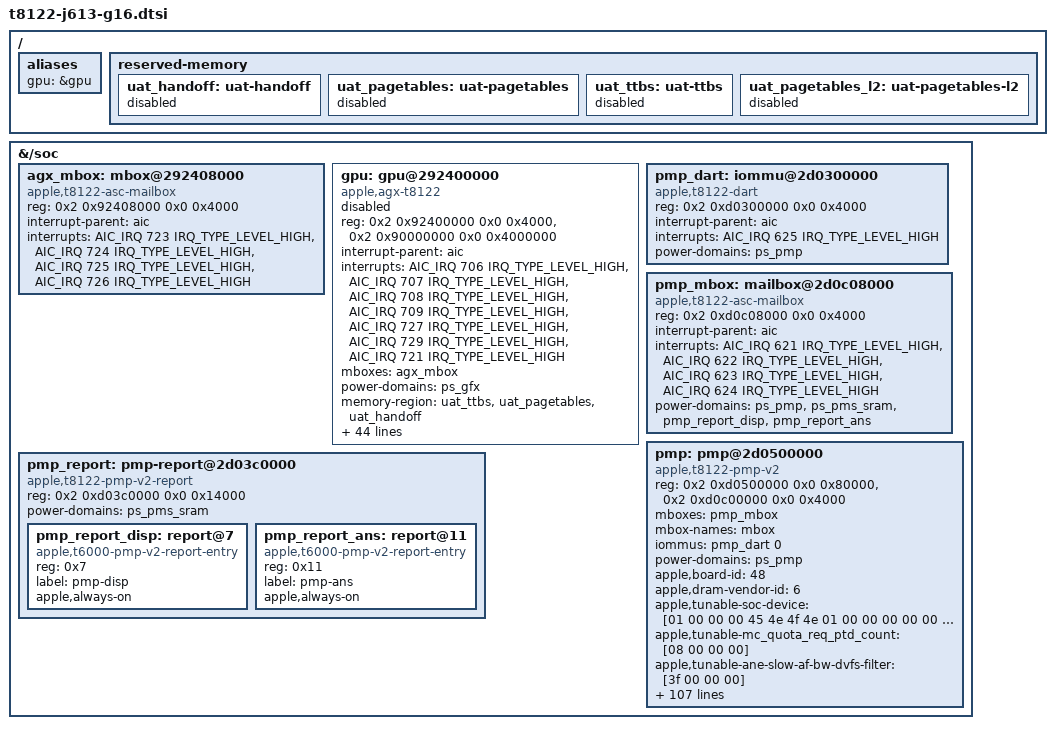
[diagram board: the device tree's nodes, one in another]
// SPDX-License-Identifier: GPL-2.0+ OR MIT
/*
 * J613 GPU on the 25G83 (RTKit-3255.160.4) firmware path, and its PMP.
 * Generated by make-j613-g16-dtsi.py from the J613 ADT iBoot 25G83 passes to macOS
 * (/arm-io/sgx, pmp, iop-pmp-nub, dart-pmp, /chosen). See the script for the contract.
 */

/ {
	aliases {
		gpu = &gpu;	/* m1n1 dt_set_gpu() finds the node through this alias */
	};

	reserved-memory {
		/* Filled, linked and enabled by the bootloader; no placeholder reg. */
		uat_handoff: uat-handoff { status = "disabled"; };
		uat_pagetables: uat-pagetables { status = "disabled"; };
		uat_ttbs: uat-ttbs { status = "disabled"; };
		uat_pagetables_l2: uat-pagetables-l2 { status = "disabled"; };
	};
};

&{/soc} {
	agx_mbox: mbox@292408000 {
		compatible = "apple,t8122-asc-mailbox", "apple,asc-mailbox-v4";
		reg = <0x2 0x92408000 0x0 0x4000>;
		interrupt-parent = <&aic>;
		interrupts = <AIC_IRQ 723 IRQ_TYPE_LEVEL_HIGH>,
			<AIC_IRQ 724 IRQ_TYPE_LEVEL_HIGH>,
			<AIC_IRQ 725 IRQ_TYPE_LEVEL_HIGH>,
			<AIC_IRQ 726 IRQ_TYPE_LEVEL_HIGH>;
		interrupt-names = "send-empty", "send-not-empty",
			"recv-empty", "recv-not-empty";
		#mbox-cells = <0>;
	};

	gpu: gpu@292400000 {
		compatible = "apple,agx-t8122";
		reg = <0x2 0x92400000 0x0 0x4000>,
			<0x2 0x90000000 0x0 0x4000000>;
		reg-names = "asc", "sgx";
		interrupt-parent = <&aic>;
		interrupts = <AIC_IRQ 706 IRQ_TYPE_LEVEL_HIGH>,
			<AIC_IRQ 707 IRQ_TYPE_LEVEL_HIGH>,
			<AIC_IRQ 708 IRQ_TYPE_LEVEL_HIGH>,
			<AIC_IRQ 709 IRQ_TYPE_LEVEL_HIGH>,
			<AIC_IRQ 727 IRQ_TYPE_LEVEL_HIGH>,
			<AIC_IRQ 729 IRQ_TYPE_LEVEL_HIGH>,
			<AIC_IRQ 721 IRQ_TYPE_LEVEL_HIGH>;
		mboxes = <&agx_mbox>;
		power-domains = <&ps_gfx>;
		/* The bootloader replaces these with all six regions, in g16 order. */
		memory-region = <&uat_ttbs>, <&uat_pagetables>, <&uat_handoff>;
		memory-region-names = "ttbs", "pagetables", "handoff";
		apple,pmp = <&pmp>;
		apple,j613-native-gpu;

		/* Controller gains copied from the J613 ADT sgx gpu-* values. */
		apple,min-sram-microvolt = <790000>;
		/* ADT gpu-perf-base-pstate */
		apple,perf-base-pstate = <1>;

		/* ADT /arm-io/sgx gpu-* tunables, ADT name minus the "gpu-" prefix */
		apple,avg-power-filter-tc-ms = <40>;
		apple,avg-power-ki-only = <70.0>;
		apple,avg-power-kp = <1.95>;
		apple,avg-power-min-duty-cycle = <30>;
		apple,avg-power-target-filter-tc = <1>;
		apple,fast-die0-integral-gain = <450.0>;
		apple,fast-die0-proportional-gain = <34.0>;
		apple,perf-boost-ce-step = <50>;
		apple,perf-boost-min-util = <90>;
		apple,perf-filter-drop-threshold = <0>;
		apple,perf-filter-time-constant = <5>;
		apple,perf-filter-time-constant2 = <200>;
		apple,perf-integral-gain = <0.7975>;
		apple,perf-integral-gain2 = <0.7975>;
		apple,perf-integral-min-clamp = <0>;
		apple,perf-proportional-gain = <5.4>;
		apple,perf-proportional-gain2 = <5.4>;
		apple,perf-tgt-utilization = <85>;
		apple,power-sample-period = <8>;
		apple,ppm-filter-time-constant-ms = <100>;
		apple,ppm-ki = <97.1>;
		apple,ppm-kp = <2.9>;
		apple,pwr-filter-time-constant = <313>;
		apple,pwr-integral-gain = <0.0202129>;
		apple,pwr-integral-min-clamp = <0>;
		apple,pwr-min-duty-cycle = <30>;
		apple,pwr-proportional-gain = <5.2831855>;
		apple,pwr-sample-period-aic-clks = <200000>;
		apple,se-engagement-criteria = <600>;
		apple,se-filter-time-constant = <9>;
		apple,se-filter-time-constant-1 = <3>;
		apple,se-inactive-threshold = <2500>;
		apple,se-ki = <-50.0>;
		apple,se-ki-1 = <-100.0>;
		apple,se-kp = <-5.0>;
		apple,se-kp-1 = <-10.0>;
		apple,se-reset-criteria = <50>;
		apple,se-target = <1400>;

		apple,fast-die0-release-temp = <80>;
		status = "disabled";
	};

	pmp_report: pmp-report@2d03c0000 {
		compatible = "apple,t8122-pmp-v2-report";
		reg = <0x2 0xd03c0000 0x0 0x14000>;
		power-domains = <&ps_pms_sram>;
		#address-cells = <1>;
		#size-cells = <0>;

		pmp_report_disp: report@7 {
			compatible = "apple,t6000-pmp-v2-report-entry";
			reg = <0x7>;
			label = "pmp-disp";
			#power-domain-cells = <0>;
			apple,always-on;
		};

		pmp_report_ans: report@11 {
			compatible = "apple,t6000-pmp-v2-report-entry";
			reg = <0x11>;
			label = "pmp-ans";
			#power-domain-cells = <0>;
			apple,always-on;
		};
	};

	pmp_dart: iommu@2d0300000 {
		compatible = "apple,t8122-dart", "apple,t8110-dart";
		reg = <0x2 0xd0300000 0x0 0x4000>;
		#iommu-cells = <1>;
		interrupt-parent = <&aic>;
		interrupts = <AIC_IRQ 625 IRQ_TYPE_LEVEL_HIGH>;
		power-domains = <&ps_pmp>;
	};

	pmp_mbox: mailbox@2d0c08000 {
		compatible = "apple,t8122-asc-mailbox", "apple,asc-mailbox-v4";
		reg = <0x2 0xd0c08000 0x0 0x4000>;
		interrupt-parent = <&aic>;
		interrupts = <AIC_IRQ 621 IRQ_TYPE_LEVEL_HIGH>,
			<AIC_IRQ 622 IRQ_TYPE_LEVEL_HIGH>,
			<AIC_IRQ 623 IRQ_TYPE_LEVEL_HIGH>,
			<AIC_IRQ 624 IRQ_TYPE_LEVEL_HIGH>;
		interrupt-names = "send-empty", "send-not-empty",
			"recv-empty", "recv-not-empty";
		#mbox-cells = <0>;
		/* The report entries are listed so fw_devlink seeds DISP/ANS before the PMP starts. */
		power-domains = <&ps_pmp>, <&ps_pms_sram>, <&pmp_report_disp>, <&pmp_report_ans>;
	};

	pmp: pmp@2d0500000 {
		compatible = "apple,t8122-pmp-v2", "apple,t6000-pmp-v2";
		reg = <0x2 0xd0500000 0x0 0x80000>,
		      <0x2 0xd0c00000 0x0 0x4000>;
		reg-names = "pmp", "asc";
		mboxes = <&pmp_mbox>;
		mbox-names = "mbox";
		iommus = <&pmp_dart 0>;
		power-domains = <&ps_pmp>;
		apple,board-id = <48>;
		apple,dram-vendor-id = <6>;
		apple,tunable-soc-device = [01 00 00 00 45 4e 4f 4e 01 00 00 00 00 00 00 00 00 00 00 00 00 00 00 00 01 00 00 00 00 00 00 00 00 00 00 00 00 00 00 00 00 00 00 00 00 00 00 00 00 00 00 00 00 00 00 00 00 00 00 00 00 00 00 00 00 00 00 00 00 00 00 00 00 00 00 00 00 00 00 00 00 00 00 00 00 00 00 00 00 00 00 00 00 00 00 00 00 00 00 00 00 00 00 00 00 00 00 00 00 00 00 00 00 00 00 00 44 43 53 00 00 00 00 00 02 00 00 00 45 4e 4f 4e 01 00 00 00 10 00 00 00 00 00 00 00 00 00 00 00 02 00 00 00 00 00 00 00 00 00 00 00 00 00 00 00 00 00 00 00 00 00 00 00 00 00 00 00 00 00 00 00 00 00 00 00 00 00 00 00 00 00 00 00 00 00 00 00 00 00 00 00 00 00 00 00 00 00 00 00 00 00 00 00 00 00 00 00 00 00 00 00 00 00 00 00 00 00 00 00 00 00 00 00 00 00 00 00 00 00 00 00 41 4d 43 43 00 00 00 00 13 00 00 00 45 4e 4f 4e 01 00 00 00 01 00 00 00 00 00 00 00 00 00 00 00 02 00 00 00 00 00 00 00 00 00 00 00 00 00 00 00 00 00 00 00 00 00 00 00 00 00 00 00 00 00 00 00 00 00 00 00 00 00 00 00 00 00 00 00 00 00 00 00 00 00 00 00 00 00 00 00 00 00 00 00 00 00 00 00 00 00 00 00 00 00 00 00 00 00 00 00 00 00 00 00 00 00 00 00 00 00 00 00 00 00 00 00 49 4f 41 30 00 00 00 00 14 00 00 00 45 4e 4f 4e 01 00 00 00 01 00 00 00 00 00 00 00 00 00 00 00 02 00 00 00 00 00 00 00 00 00 00 00 00 00 00 00 00 00 00 00 00 00 00 00 00 00 00 00 00 00 00 00 00 00 00 00 00 00 00 00 00 00 00 00 00 00 00 00 00 00 00 00 00 00 00 00 00 00 00 00 00 00 00 00 00 00 00 00 00 00 00 00 00 00 00 00 00 00 00 00 00 00 00 00 00 00 00 00 00 00 00 00 49 4f 41 31 00 00 00 00 10 00 00 00 45 4e 4f 4e 01 00 00 00 00 00 00 00 15 00 00 00 00 00 00 00 02 00 00 00 00 00 00 00 00 00 00 00 00 00 00 00 00 00 00 00 00 00 00 00 00 00 00 00 00 00 00 00 00 00 00 00 00 00 00 00 00 00 00 00 00 00 00 00 00 00 00 00 00 00 00 00 00 00 00 00 00 00 00 00 00 00 00 00 00 00 00 00 00 00 00 00 00 00 00 00 00 00 00 00 00 00 00 00 00 00 00 00 53 4f 43 2d 41 4f 4e 00 11 00 00 00 45 4e 4f 4e 01 00 00 00 00 00 00 00 16 00 00 00 00 00 00 00 02 00 00 00 00 00 00 00 00 00 00 00 00 00 00 00 00 00 00 00 00 00 00 00 00 00 00 00 00 00 00 00 00 00 00 00 00 00 00 00 00 00 00 00 00 00 00 00 00 00 00 00 00 00 00 00 00 00 00 00 00 00 00 00 00 00 00 00 00 00 00 00 00 00 00 00 00 00 00 00 00 00 00 00 00 00 00 00 00 00 00 00 53 4f 43 2d 52 45 53 54 03 00 00 00 45 4e 4f 4e 03 00 00 00 01 00 00 00 00 00 00 00 00 00 00 00 00 00 00 00 02 00 00 00 00 00 00 00 00 00 00 00 00 00 00 00 02 00 00 00 00 00 00 00 00 00 00 00 00 00 00 00 00 00 00 00 00 00 00 00 00 00 00 00 00 00 00 00 00 00 00 00 00 00 00 00 00 00 00 00 00 00 00 00 00 00 00 00 00 00 00 00 00 00 00 00 00 00 00 00 00 00 00 00 00 00 00 00 45 41 43 43 30 00 00 00 04 00 00 00 45 4e 4f 4e 03 00 00 00 02 00 00 00 00 00 00 00 00 00 00 00 00 00 00 00 02 00 00 00 00 00 00 00 00 00 00 00 00 00 00 00 02 00 00 00 00 00 00 00 00 00 00 00 00 00 00 00 00 00 00 00 00 00 00 00 00 00 00 00 00 00 00 00 00 00 00 00 00 00 00 00 00 00 00 00 00 00 00 00 00 00 00 00 00 00 00 00 00 00 00 00 00 00 00 00 00 00 00 00 00 00 00 00 50 41 43 43 30 00 00 00 05 00 00 00 5f 58 46 47 03 00 00 00 01 00 00 00 00 00 00 00 00 00 00 00 00 00 00 00 02 00 00 00 00 00 00 00 00 00 00 00 00 00 00 00 02 00 00 00 00 00 00 00 00 00 00 00 00 00 00 00 00 00 00 00 00 00 00 00 00 00 00 00 00 00 00 00 00 00 00 00 00 00 00 00 00 00 00 00 00 00 00 00 00 00 00 00 00 00 00 00 00 00 00 00 00 00 00 00 00 00 00 00 00 00 00 00 41 47 58 00 00 00 00 00 06 00 00 00 45 4e 4f 4e 03 00 00 00 01 00 00 00 00 00 00 00 00 00 00 00 00 00 00 00 02 00 00 00 00 00 00 00 00 00 00 00 00 00 00 00 02 00 00 00 00 00 00 00 00 00 00 00 00 00 00 00 00 00 00 00 00 00 00 00 00 00 00 00 00 00 00 00 00 00 00 00 00 00 00 00 00 00 00 00 00 00 00 00 00 00 00 00 00 00 00 00 00 00 00 00 00 00 00 00 00 00 00 00 00 00 00 00 41 4e 45 30 00 00 00 00 07 00 00 00 45 4e 4f 4e 01 00 00 00 00 00 00 00 00 00 00 00 00 00 00 00 02 00 00 00 00 00 00 00 00 00 00 00 00 00 00 00 00 00 00 00 01 00 00 00 03 00 00 00 00 00 00 00 00 00 00 00 00 00 00 00 00 00 00 00 00 00 00 00 00 00 00 00 00 00 00 00 00 00 00 00 00 00 00 00 00 00 00 00 00 00 00 00 00 00 00 00 00 00 00 00 00 00 00 00 00 00 00 00 00 00 00 00 49 53 50 00 00 00 00 00 08 00 00 00 45 4e 4f 4e 0a 00 00 00 00 00 00 00 00 00 00 00 00 00 00 00 03 00 00 00 02 00 00 00 00 00 00 00 00 00 00 00 00 00 00 00 02 00 00 00 03 00 00 00 00 00 00 00 00 00 00 00 00 00 00 00 00 00 00 00 00 00 00 00 00 00 00 00 00 00 00 00 00 00 00 00 00 00 00 00 00 00 00 00 00 00 00 00 00 00 00 00 00 00 00 00 00 00 00 00 00 00 00 00 00 00 00 00 44 49 53 50 00 00 00 00 09 00 00 00 45 4e 4f 4e 0a 00 00 00 00 00 00 00 00 00 00 00 00 00 00 00 04 00 00 00 02 00 00 00 00 00 00 00 00 00 00 00 00 00 00 00 02 00 00 00 03 00 00 00 00 00 00 00 00 00 00 00 00 00 00 00 00 00 00 00 00 00 00 00 00 00 00 00 00 00 00 00 00 00 00 00 00 00 00 00 00 00 00 00 00 00 00 00 00 00 00 00 00 00 00 00 00 00 00 00 00 00 00 00 00 00 00 00 44 49 53 50 45 58 54 00 0a 00 00 00 45 4e 4f 4e 01 00 00 00 00 00 00 00 00 00 00 00 00 00 00 00 02 00 00 00 00 00 00 00 00 00 00 00 00 00 00 00 00 00 00 00 02 00 00 00 00 00 00 00 00 00 00 00 00 00 00 00 00 00 00 00 00 00 00 00 00 00 00 00 00 00 00 00 00 00 00 00 00 00 00 00 00 00 00 00 00 00 00 00 00 00 00 00 00 00 00 00 00 00 00 00 00 00 00 00 00 00 00 00 00 00 00 00 41 56 45 00 00 00 00 00 0b 00 00 00 45 4e 4f 4e 01 00 00 00 00 00 00 00 14 00 00 00 00 00 00 00 02 00 00 00 00 00 00 00 00 00 00 00 00 00 00 00 00 00 00 00 02 00 00 00 00 00 00 00 00 00 00 00 00 00 00 00 00 00 00 00 00 00 00 00 00 00 00 00 00 00 00 00 00 00 00 00 00 00 00 00 00 00 00 00 00 00 00 00 00 00 00 00 00 00 00 00 00 00 00 00 00 00 00 00 00 00 00 00 00 00 00 00 41 56 44 00 00 00 00 00 0c 00 00 00 45 4e 4f 4e 01 00 00 00 00 00 00 00 00 00 00 00 00 00 00 00 02 00 00 00 00 00 00 00 00 00 00 00 00 00 00 00 00 00 00 00 02 00 00 00 00 00 00 00 00 00 00 00 00 00 00 00 00 00 00 00 00 00 00 00 00 00 00 00 00 00 00 00 00 00 00 00 00 00 00 00 00 00 00 00 00 00 00 00 00 00 00 00 00 00 00 00 00 00 00 00 00 00 00 00 00 00 00 00 00 00 00 00 4d 53 52 00 00 00 00 00 0d 00 00 00 45 4e 4f 4e 01 00 00 00 00 00 00 00 00 00 00 00 00 00 00 00 02 00 00 00 00 00 00 00 00 00 00 00 00 00 00 00 00 00 00 00 02 00 00 00 00 00 00 00 00 00 00 00 00 00 00 00 00 00 00 00 00 00 00 00 00 00 00 00 00 00 00 00 00 00 00 00 00 00 00 00 00 00 00 00 00 00 00 00 00 00 00 00 00 00 00 00 00 00 00 00 00 00 00 00 00 00 00 00 00 00 00 00 4a 50 45 47 00 00 00 00 0e 00 00 00 45 4e 4f 4e 01 00 00 00 00 00 00 00 00 00 00 00 00 00 00 00 02 00 00 00 00 00 00 00 00 00 00 00 00 00 00 00 00 00 00 00 02 00 00 00 03 00 00 00 00 00 00 00 00 00 00 00 00 00 00 00 00 00 00 00 00 00 00 00 00 00 00 00 00 00 00 00 00 00 00 00 00 00 00 00 00 00 00 00 00 00 00 00 00 00 00 00 00 00 00 00 00 00 00 00 00 00 00 00 00 00 00 00 53 43 4f 44 45 43 00 00 0f 00 00 00 5f 52 54 4c 00 00 00 00 00 00 00 00 00 00 00 00 00 00 00 00 00 00 00 00 00 00 00 00 00 00 00 00 00 00 00 00 00 00 00 00 02 00 00 00 00 00 00 00 00 00 00 00 00 00 00 00 00 00 00 00 00 00 00 00 00 00 00 00 00 00 00 00 00 00 00 00 00 00 00 00 00 00 00 00 00 00 00 00 00 00 00 00 00 00 00 00 00 00 00 00 00 00 00 00 00 00 00 00 00 00 00 00 4c 54 52 00 00 00 00 00 12 00 00 00 45 4e 4f 4e 00 00 00 00 00 00 00 00 00 00 00 00 00 00 00 00 02 00 00 00 00 00 00 00 00 00 00 00 00 00 00 00 00 00 00 00 02 00 00 00 00 00 00 00 00 00 00 00 00 00 00 00 00 00 00 00 00 00 00 00 00 00 00 00 00 00 00 00 00 00 00 00 00 00 00 00 00 00 00 00 00 00 00 00 00 00 00 00 00 00 00 00 00 00 00 00 00 00 00 00 00 00 00 00 00 00 00 00 41 4e 53 00 00 00 00 00];
		apple,tunable-mc_quota_req_ptd_count = [08 00 00 00];
		apple,tunable-ane-slow-af-bw-dvfs-filter = [3f 00 00 00];
		apple,tunable-mc_cmd_ptd_count = [02 00 00 00];
		apple,tunable-sochot-sensors = [01 00 00 00 02 00 00 00 03 00 00 00 04 00 00 00 05 00 00 00 06 00 00 00 09 00 00 00 0a 00 00 00 0b 00 00 00];
		apple,tunable-ptd-range = [01 00 00 00 00 00 00 00 01 00 00 00 00 00 00 00 4e 55 4c 4c 00 00 00 00 00 00 00 00 00 00 00 00 02 00 00 00 01 00 00 00 01 00 00 00 00 00 00 00 50 4d 50 2d 53 54 41 54 55 53 00 00 00 00 00 00 03 00 00 00 08 00 00 00 04 00 00 00 00 00 00 00 44 56 46 53 2d 53 54 41 54 45 00 00 00 00 00 00 04 00 00 00 0c 00 00 00 04 00 00 00 00 00 00 00 50 4d 50 54 4f 4f 4c 00 00 00 00 00 00 00 00 00 05 00 00 00 10 00 00 00 10 00 00 00 00 00 00 00 50 4d 53 2d 50 4d 47 52 2d 50 4b 54 00 00 00 00 06 00 00 00 20 00 00 00 10 00 00 00 00 00 00 00 50 4d 53 2d 44 50 45 2d 50 4b 54 00 00 00 00 00 07 00 00 00 30 00 00 00 10 00 00 00 00 00 00 00 50 4d 53 2d 44 45 56 43 2d 50 4b 54 00 00 00 00 09 00 00 00 40 00 00 00 c0 00 00 00 00 00 00 00 53 4f 43 2d 44 45 56 2d 50 4b 54 00 00 00 00 00 0a 00 00 00 00 01 00 00 08 00 00 00 00 00 00 00 53 4f 43 2d 44 45 56 2d 50 53 2d 52 45 51 00 00 0b 00 00 00 08 01 00 00 08 00 00 00 00 00 00 00 53 4f 43 2d 44 45 56 2d 50 53 2d 41 43 4b 00 00 0c 00 00 00 10 01 00 00 10 00 00 00 00 00 00 00 53 4f 43 2d 44 45 56 2d 44 56 46 53 00 00 00 00 0d 00 00 00 20 01 00 00 08 00 00 00 00 00 00 00 53 4f 43 2d 44 45 56 2d 42 57 52 00 00 00 00 00 0e 00 00 00 28 01 00 00 0a 00 00 00 00 00 00 00 4d 43 2d 44 52 56 2d 54 4f 2d 43 54 52 4c 00 00 14 00 00 00 39 01 00 00 01 00 00 00 00 00 00 00 41 56 44 2d 4e 52 47 00 00 00 00 00 00 00 00 00 15 00 00 00 3a 01 00 00 01 00 00 00 00 00 00 00 53 4f 43 2d 41 4f 4e 2d 4e 52 47 00 00 00 00 00 16 00 00 00 3b 01 00 00 01 00 00 00 00 00 00 00 53 4f 43 2d 52 45 53 54 2d 4e 52 47 00 00 00 00 1e 00 00 00 40 01 00 00 09 00 00 00 00 00 00 00 4d 43 2d 43 54 52 4c 2d 54 4f 2d 44 52 56 00 00 1f 00 00 00 49 01 00 00 02 00 00 00 0c 00 00 00 46 41 53 54 2d 44 49 45 2d 43 45 00 00 00 00 00 20 00 00 00 4b 01 00 00 07 00 00 00 0d 00 00 00 53 4d 43 2d 54 4f 2d 50 50 4d 00 00 00 00 00 00 21 00 00 00 52 01 00 00 01 00 00 00 00 00 00 00 50 4d 55 2d 54 4f 2d 43 4c 50 43 00 00 00 00 00 22 00 00 00 53 01 00 00 01 00 00 00 0b 00 00 00 4c 54 53 2d 56 4f 4c 54 2d 43 41 50 00 00 00 00 40 00 00 00 68 01 00 00 05 00 00 00 0e 00 00 00 50 50 4d 2d 54 4f 2d 53 4d 43 00 00 00 00 00 00 41 00 00 00 6d 01 00 00 05 00 00 00 0f 00 00 00 43 4c 50 43 2d 54 4f 2d 53 4d 43 00 00 00 00 00 42 00 00 00 72 01 00 00 08 00 00 00 00 00 00 00 47 46 58 2d 54 4f 2d 53 4d 43 00 00 00 00 00 00 43 00 00 00 7a 01 00 00 02 00 00 00 00 00 00 00 46 41 53 54 2d 44 49 45 2d 54 4f 2d 53 4d 43 00 44 00 00 00 7c 01 00 00 01 00 00 00 00 00 00 00 4d 43 2d 43 54 52 4c 2d 54 4f 2d 53 4d 43 00 00 52 00 00 00 b8 01 00 00 01 00 00 00 00 00 00 00 4c 54 53 2d 54 4f 2d 47 46 58 00 00 00 00 00 00 53 00 00 00 b9 01 00 00 01 00 00 00 00 00 00 00 50 4d 55 2d 54 4f 2d 47 46 58 00 00 00 00 00 00];
		apple,tunable-sram-index = [01 00 00 00];
		apple,tunable-no-shutdown = [01 00 00 00];
		apple,tunable-dvfs-domain = [01 00 00 00 05 00 00 00 00 00 00 00 44 43 53 00 00 00 00 00 00 00 00 00 00 00 00 00 02 00 00 00 03 00 00 00 00 00 00 00 53 4f 43 00 00 00 00 00 00 00 00 00 00 00 00 00 03 00 00 00 03 00 00 00 00 00 00 00 44 49 53 50 5f 49 4e 54 00 00 00 00 00 00 00 00 04 00 00 00 04 00 00 00 00 00 00 00 44 49 53 50 5f 45 58 54 00 00 00 00 00 00 00 00];
		apple,tunable-fast-die-ctrl-ce-map = [01 00 00 00 00 00 00 00 00 00 00 00 01 00 00 00 00 00 00 00 00 00 00 00 00 00 00 00 45 41 43 43 00 00 00 00 00 00 00 00 00 00 00 00 02 00 00 00 00 00 00 00 01 00 00 00 02 00 00 00 03 00 00 00 00 00 00 00 00 00 00 00 50 41 43 43 5f 41 4e 45 00 00 00 00 00 00 00 00];
		apple,tunable-ane-fast-af-bw-threshold = [00 00 05 00 00 00 00 00 00 00 00 00 00 00 00 00 00 00 0e 00 00 00 00 00 00 00 04 00 06 00 00 00 00 00 00 00 00 00 00 00 00 00 0d 00 06 00 00 00];
		apple,tunable-user-power-managed = [01 00 00 00];
		apple,tunable-dcs-rd-bwr-threshold = [33 b3 0b 00 00 80 18 00 99 19 22 00 33 b3 2b 00 33 33 33 00];
		apple,tunable-lts-voltage = [01 00 00 00 03 00 00 00 03 00 00 00 01 00 00 00 45 41 43 43 00 00 00 00 02 00 00 00 03 00 00 00 04 00 00 00 02 00 00 00 50 41 43 43 00 00 00 00 03 00 00 00 01 00 00 00 06 00 00 00 00 00 00 00 41 4e 45 00 00 00 00 00 04 00 00 00 03 00 00 00 05 00 00 00 04 00 00 00 41 47 58 00 00 00 00 00];
		apple,tunable-bwr-catch-up-factor = [00 00 01 00];
		apple,tunable-controller = [01 00 00 00 1f 00 00 00 43 00 00 00 00 00 00 00 00 00 00 00 44 49 45 2d 54 45 4d 50 00 00 00 00 00 00 00 00 00 00 00 00 00 00 00 00 00 00 00 00 00 00 00 00 02 00 00 00 00 00 00 00 00 00 00 00 00 00 00 00 00 00 00 00 44 43 53 2d 42 57 00 00 00 00 00 00 00 00 00 00 00 00 00 00 00 00 00 00 00 00 00 00 00 00 00 00 03 00 00 00 00 00 00 00 00 00 00 00 00 00 00 00 00 00 00 00 41 47 58 2d 53 4c 4f 57 2d 41 46 2d 52 44 2d 42 57 00 00 00 00 00 00 00 00 00 00 00 00 00 00 00 04 00 00 00 00 00 00 00 00 00 00 00 00 00 00 00 00 00 00 00 41 47 58 2d 46 41 53 54 2d 41 46 2d 52 44 2d 42 57 00 00 00 00 00 00 00 00 00 00 00 00 00 00 00 05 00 00 00 00 00 00 00 00 00 00 00 00 00 00 00 00 00 00 00 41 47 58 2d 53 4c 4f 57 2d 41 46 2d 57 52 2d 42 57 00 00 00 00 00 00 00 00 00 00 00 00 00 00 00 06 00 00 00 00 00 00 00 00 00 00 00 00 00 00 00 00 00 00 00 41 47 58 2d 46 41 53 54 2d 41 46 2d 57 52 2d 42 57 00 00 00 00 00 00 00 00 00 00 00 00 00 00 00 07 00 00 00 00 00 00 00 00 00 00 00 00 00 00 00 00 00 00 00 41 47 58 2d 53 4c 4f 57 2d 44 43 53 2d 42 57 00 00 00 00 00 00 00 00 00 00 00 00 00 00 00 00 00 08 00 00 00 00 00 00 00 00 00 00 00 00 00 00 00 00 00 00 00 41 47 58 2d 46 41 53 54 2d 44 43 53 2d 42 57 00 00 00 00 00 00 00 00 00 00 00 00 00 00 00 00 00 09 00 00 00 00 00 00 00 00 00 00 00 00 00 00 00 00 00 00 00 41 4e 45 2d 53 4c 4f 57 2d 44 43 53 2d 42 57 00 00 00 00 00 00 00 00 00 00 00 00 00 00 00 00 00 0a 00 00 00 00 00 00 00 00 00 00 00 00 00 00 00 00 00 00 00 41 4e 45 2d 46 41 53 54 2d 44 43 53 2d 42 57 00 00 00 00 00 00 00 00 00 00 00 00 00 00 00 00 00 0b 00 00 00 00 00 00 00 00 00 00 00 00 00 00 00 00 00 00 00 41 4e 45 2d 53 4c 4f 57 2d 41 46 2d 42 57 00 00 00 00 00 00 00 00 00 00 00 00 00 00 00 00 00 00 0c 00 00 00 00 00 00 00 00 00 00 00 00 00 00 00 00 00 00 00 41 4e 45 2d 46 41 53 54 2d 41 46 2d 42 57 00 00 00 00 00 00 00 00 00 00 00 00 00 00 00 00 00 00 0d 00 00 00 00 00 00 00 00 00 00 00 00 00 00 00 00 00 00 00 44 43 53 2d 42 57 52 00 00 00 00 00 00 00 00 00 00 00 00 00 00 00 00 00 00 00 00 00 00 00 00 00 0e 00 00 00 00 00 00 00 00 00 00 00 00 00 00 00 00 00 00 00 44 43 53 2d 52 44 2d 42 57 52 00 00 00 00 00 00 00 00 00 00 00 00 00 00 00 00 00 00 00 00 00 00 0f 00 00 00 00 00 00 00 00 00 00 00 00 00 00 00 00 00 00 00 44 43 53 2d 57 52 2d 42 57 52 00 00 00 00 00 00 00 00 00 00 00 00 00 00 00 00 00 00 00 00 00 00 10 00 00 00 00 00 00 00 00 00 00 00 00 00 00 00 00 00 00 00 53 4f 43 30 2d 52 44 2d 42 57 52 00 00 00 00 00 00 00 00 00 00 00 00 00 00 00 00 00 00 00 00 00 11 00 00 00 00 00 00 00 00 00 00 00 00 00 00 00 00 00 00 00 53 4f 43 30 2d 57 52 2d 42 57 52 00 00 00 00 00 00 00 00 00 00 00 00 00 00 00 00 00 00 00 00 00 12 00 00 00 00 00 00 00 00 00 00 00 00 00 00 00 00 00 00 00 53 4f 43 31 2d 52 44 2d 42 57 52 00 00 00 00 00 00 00 00 00 00 00 00 00 00 00 00 00 00 00 00 00 13 00 00 00 00 00 00 00 00 00 00 00 00 00 00 00 00 00 00 00 53 4f 43 31 2d 57 52 2d 42 57 52 00 00 00 00 00 00 00 00 00 00 00 00 00 00 00 00 00 00 00 00 00 14 00 00 00 0e 00 00 00 1e 00 00 00 00 00 00 00 00 00 00 00 4d 45 4d 2d 43 41 43 48 45 00 00 00 00 00 00 00 00 00 00 00 00 00 00 00 00 00 00 00 00 00 00 00 15 00 00 00 00 00 00 00 00 00 00 00 00 00 00 00 00 00 00 00 49 4f 41 30 2d 41 46 4e 43 2d 42 57 00 00 00 00 00 00 00 00 00 00 00 00 00 00 00 00 00 00 00 00 16 00 00 00 00 00 00 00 00 00 00 00 00 00 00 00 00 00 00 00 49 4f 41 31 2d 41 46 4e 43 2d 42 57 00 00 00 00 00 00 00 00 00 00 00 00 00 00 00 00 00 00 00 00 17 00 00 00 52 00 00 00 22 00 00 00 00 00 00 00 00 00 00 00 4c 49 46 45 54 49 4d 45 2d 53 45 52 56 4f 00 00 00 00 00 00 00 00 00 00 00 00 00 00 00 00 00 00];
		apple,tunable-ioa0-afnc-bw-threshold = [66 a6 19 00 00 00 00 00 00 00 00 00 00 00 00 00 33 33 22 00 00 00 00 00 66 a6 18 00 03 00 00 00 00 00 00 00 00 00 00 00 33 33 21 00 03 00 00 00];
		apple,tunable-agx-fast-af-wr-bw-dvfs-filter = [f0 03 00 00];
		apple,tunable-agx-slow-af-rd-bw-dvfs-filter = [0e 00 00 00];
		apple,tunable-soc-device-ps-group = [f0 ff 03 00 00 00 00 00];
		apple,tunable-mc_quota_rsp_ptd_count = [08 00 00 00];
		apple,tunable-lts-ctrl-ts = [00 00 05 00];
		apple,tunable-ane-slow-dcs-bw-threshold = [8f c2 12 00 00 00 00 00 00 00 00 00 00 00 00 00 5c 8f 25 00 00 00 00 00 8f c2 11 00 03 00 00 00 99 99 36 00 00 00 00 00 5c 8f 24 00 03 00 00 00 c2 f5 45 00 00 00 00 00 99 99 35 00 03 00 00 00 00 00 00 00 00 00 00 00 c2 f5 44 00 03 00 00 00];
		apple,tunable-ioa1-afnc-bw-threshold = [66 a6 19 00 00 00 00 00 00 00 00 00 00 00 00 00 33 33 22 00 00 00 00 00 66 a6 18 00 03 00 00 00 00 00 00 00 00 00 00 00 33 33 21 00 03 00 00 00];
		apple,tunable-dcs-bw-threshold = [8f c2 12 00 00 00 00 00 00 00 00 00 00 00 00 00 5c 8f 25 00 00 00 00 00 8f c2 11 00 03 00 00 00 99 99 36 00 00 00 00 00 5c 8f 24 00 03 00 00 00 c2 f5 45 00 00 00 00 00 99 99 35 00 03 00 00 00 00 00 00 00 00 00 00 00 c2 f5 44 00 03 00 00 00];
		apple,tunable-mc_cmd_ack_ptd_count = [01 00 00 00];
		apple,tunable-agx-fast-dcs-bw-dvfs-filter = [f0 03 00 00];
		apple,tunable-agx-slow-dcs-bw-dvfs-filter = [0e 00 00 00];
		apple,tunable-ane-fast-dcs-bw-threshold = [00 00 05 00 00 00 00 00 00 00 00 00 00 00 00 00 00 00 0e 00 00 00 00 00 00 00 04 00 06 00 00 00 00 00 2a 00 00 00 00 00 00 00 0d 00 06 00 00 00 00 00 46 00 00 00 00 00 00 00 29 00 06 00 00 00 00 00 00 00 00 00 00 00 00 00 45 00 06 00 00 00];
		apple,tunable-ane-fast-af-bw-dvfs-filter = [c0 ff 1f 00];
		apple,tunable-fast-die-ctrl-loop = [01 00 00 00 00 00 00 00 00 00 00 00 1e 05 00 00 99 19 04 00 00 00 6e 00 00 00 01 00 00 00 00 00 00 00 01 00 00 00 00 00 00 00 00 00 00 00 01 00 16 00 00 00 02 00 00 00 03 00 00 00 00 00 00 00 00 00 00 00 00 00 00 00 00 00 00 00 00 00 00 00 00 00 00 00 00 00 00 00 00 00 00 00 00 00 00 00 00 00 00 00 00 00 00 00 00 00 00 00 00 00 00 00 00 00 00 00 45 41 43 43 00 00 00 00 00 00 00 00 00 00 00 00 02 00 00 00 00 00 00 00 01 00 00 00 1e 05 00 00 99 19 04 00 00 00 6e 00 00 00 01 00 00 00 00 00 00 00 01 00 00 00 00 00 00 00 00 00 00 00 01 00 16 00 00 00 04 00 00 00 05 00 00 00 06 00 00 00 00 00 00 00 00 00 00 00 00 00 00 00 00 00 00 00 00 00 00 00 00 00 00 00 00 00 00 00 00 00 00 00 00 00 00 00 00 00 00 00 00 00 00 00 00 00 00 00 00 00 00 00 50 41 43 43 00 00 00 00 00 00 00 00 00 00 00 00 03 00 00 00 00 00 00 00 02 00 00 00 1e 05 00 00 99 19 04 00 00 00 6e 00 00 00 01 00 00 00 00 00 00 00 01 00 00 00 00 00 00 00 00 00 00 00 01 00 16 00 00 00 01 00 00 00 00 00 00 00 00 00 00 00 00 00 00 00 00 00 00 00 00 00 00 00 00 00 00 00 00 00 00 00 00 00 00 00 00 00 00 00 00 00 00 00 00 00 00 00 00 00 00 00 00 00 00 00 00 00 00 00 00 00 00 00 41 4e 45 00 00 00 00 00 00 00 00 00 00 00 00 00];
		apple,tunable-soc0-wr-bwr-threshold = [33 33 16 00 99 99 1d 00 66 66 2c 00];
		apple,tunable-agx-slow-dcs-bw-threshold = [00 00 12 00 00 00 00 00 00 00 00 00 00 00 00 00 00 00 24 00 00 00 00 00 00 00 11 00 06 00 00 00 00 00 30 00 00 00 00 00 00 00 23 00 06 00 00 00 00 00 44 00 00 00 00 00 00 00 2f 00 06 00 00 00 00 00 00 00 00 00 00 00 00 00 43 00 06 00 00 00];
		apple,tunable-soc0-rd-bwr-threshold = [33 33 16 00 99 99 1d 00 66 66 2c 00];
		apple,tunable-lts-clpc-voltage = [01 00 00 00 ee 03 00 00 00 00 69 00 00 00 6a 00 00 00 00 00 50 41 43 43 00 00 00 00];
		apple,tunable-soc1-rd-bwr-threshold = [33 33 16 00 99 99 1d 00 66 66 2c 00];
		apple,tunable-energy-counter = [01 00 00 00 01 00 00 00 05 00 00 00 01 00 00 00 41 47 58 00 00 00 00 00 00 00 00 00 00 00 00 00 02 00 00 00 01 00 00 00 05 00 00 00 02 00 00 00 41 47 58 2d 53 52 41 4d 00 00 00 00 00 00 00 00 03 00 00 00 01 00 00 00 06 00 00 00 01 00 00 00 41 4e 45 00 00 00 00 00 00 00 00 00 00 00 00 00 04 00 00 00 00 00 00 00 14 00 00 00 00 00 00 00 56 44 45 43 00 00 00 00 00 00 00 00 00 00 00 00 05 00 00 00 00 00 00 00 15 00 00 00 00 00 00 00 53 4f 43 5f 41 4f 4e 00 00 00 00 00 00 00 00 00 06 00 00 00 00 00 00 00 16 00 00 00 00 00 00 00 53 4f 43 5f 52 45 53 54 00 00 00 00 00 00 00 00];
		apple,tunable-agx-fast-dcs-bw-threshold = [00 00 01 00 00 00 00 00 00 00 00 00 00 00 00 00 00 00 0e 00 00 00 00 00 00 00 00 00 06 00 00 00 00 00 1c 00 00 00 00 00 00 00 0d 00 06 00 00 00 00 00 20 00 00 00 00 00 00 00 1b 00 06 00 00 00 00 00 00 00 00 00 00 00 00 00 1f 00 06 00 00 00];
		apple,tunable-agx-fast-af-wr-bw-threshold = [00 00 05 00 00 00 00 00 00 00 00 00 00 00 00 00 00 00 2c 00 00 00 00 00 00 00 04 00 06 00 00 00 00 00 00 00 00 00 00 00 00 00 2b 00 06 00 00 00];
		apple,tunable-lts-config = [00 00 00 00 00 00 00 00 42 bc 10 00 00 00 00 00 87 d3 0f 00 6e 00 00 00 69 00 00 00 00 00 11 00 33 b3 00 00 0e 0d 1e 03 01 00 00 00 3b 01 00 00 42 bc 10 00 00 00 00 00 87 d3 0f 00 6e 00 00 00 69 00 00 00 00 00 11 00 33 b3 00 00 2d d2 4b 00 02 00 00 00 0d 02 00 00 ca 63 00 00 00 00 00 00 f4 dd 0f 00 6e 00 00 00 69 00 00 00 00 00 11 00 33 b3 00 00 70 fd 22 03];
		apple,tunable-agx-slow-af-wr-bw-threshold = [00 00 0e 00 00 00 00 00 00 00 00 00 00 00 00 00 00 00 4c 00 00 00 00 00 00 00 0d 00 06 00 00 00 00 00 00 00 00 00 00 00 00 00 4b 00 06 00 00 00];
		apple,tunable-soc1-wr-bwr-threshold = [33 33 16 00 99 99 1d 00 66 66 2c 00];
		apple,tunable-mcache-stream = [1e 00 00 00 03 00 00 00 01 00 00 00 0b 00 00 00 0e 00 00 00 0e 00 00 00 02 00 00 00 00 00 00 00 00 00 00 00 04 00 00 00 01 00 00 00 05 00 00 00 01 00 00 00 01 00 00 00 02 00 00 00 14 00 00 00 14 00 00 00 02 00 00 00 00 00 00 00 00 00 00 00 04 00 00 00 01 00 00 00 06 00 00 00 02 00 00 00 01 00 00 00 03 00 00 00 12 00 00 00 12 00 00 00 02 00 00 00 00 00 00 00 00 00 00 00 04 00 00 00 00 00 00 00 0b 00 00 00 05 00 00 00 01 00 00 00 05 00 00 00 21 00 00 00 21 00 00 00 02 00 00 00 00 00 00 00 00 00 00 00 04 00 00 00 01 00 00 00 0e 00 00 00 04 00 00 00 01 00 00 00 10 00 00 00 15 00 00 00 15 00 00 00 02 00 00 00 00 00 00 00 00 00 00 00 04 00 00 00 00 00 00 00 11 00 00 00 04 00 00 00 01 00 00 00 11 00 00 00 16 00 00 00 16 00 00 00 02 00 00 00 00 00 00 00 00 00 00 00 04 00 00 00 01 00 00 00 13 00 00 00 04 00 00 00 01 00 00 00 12 00 00 00 17 00 00 00 17 00 00 00 02 00 00 00 00 00 00 00 00 00 00 00 04 00 00 00 01 00 00 00 24 00 00 00 04 00 00 00 01 00 00 00 12 00 00 00 18 00 00 00 18 00 00 00 02 00 00 00 00 00 00 00 00 00 00 00 04 00 00 00 01 00 00 00 1b 00 00 00 04 00 00 00 01 00 00 00 11 00 00 00 1e 00 00 00 1e 00 00 00 02 00 00 00 00 00 00 00 00 00 00 00 04 00 00 00 01 00 00 00 1c 00 00 00 04 00 00 00 01 00 00 00 12 00 00 00 1f 00 00 00 1f 00 00 00 02 00 00 00 00 00 00 00 00 00 00 00 04 00 00 00 01 00 00 00 10 00 00 00 04 00 00 00 01 00 00 00 18 00 00 00 40 00 00 00 bf 00 00 00 02 00 00 00 00 00 00 00 00 00 00 00 04 00 00 00 01 00 00 00 04 00 00 00 00 00 00 00 01 00 00 00 06 00 00 00 0d 00 00 00 0d 00 00 00 02 00 00 00 00 00 00 00 00 00 00 00 05 00 00 00 01 00 00 00 02 00 00 00 00 00 00 00 01 00 00 00 04 00 00 00 13 00 00 00 13 00 00 00 02 00 00 00 00 00 00 00 00 00 00 00 04 00 00 00 01 00 00 00 01 00 00 00 00 00 00 00 01 00 00 00 0a 00 00 00 0a 00 00 00 0c 00 00 00 02 00 00 00 00 00 00 00 00 00 00 00 04 00 00 00 01 00 00 00 1f 00 00 00 03 00 00 00 02 00 00 00 0b 00 00 00 23 00 00 00 23 00 00 00 03 00 00 00 00 00 00 00 00 00 00 00 04 00 00 00 01 00 00 00 20 00 00 00 03 00 00 00 02 00 00 00 16 00 00 00 24 00 00 00 33 00 00 00 03 00 00 00 00 00 00 00 00 00 00 00 05 00 00 00 01 00 00 00 12 00 00 00 05 00 00 00 02 00 00 00 09 00 00 00 0f 00 00 00 0f 00 00 00 03 00 00 00 00 00 00 00 00 00 00 00 04 00 00 00 01 00 00 00 15 00 00 00 07 00 00 00 02 00 00 00 0f 00 00 00 11 00 00 00 11 00 00 00 03 00 00 00 00 00 00 00 00 00 00 00 04 00 00 00 01 00 00 00 21 00 00 00 0a 00 00 00 02 00 00 00 07 00 00 00 20 00 00 00 20 00 00 00 03 00 00 00 00 00 00 00 00 00 00 00 04 00 00 00 00 00 00 00 1d 00 00 00 09 00 00 00 02 00 00 00 13 00 00 00 34 00 00 00 38 00 00 00 03 00 00 00 00 00 00 00 00 00 00 00 04 00 00 00 01 00 00 00 23 00 00 00 00 00 00 00 03 00 00 00 0c 00 00 00 19 00 00 00 19 00 00 00 01 00 00 00 00 00 00 00 00 00 00 00 04 00 00 00 01 00 00 00 19 00 00 00 08 00 00 00 03 00 00 00 01 00 00 00 03 00 00 00 03 00 00 00 01 00 00 00 00 00 00 00 00 00 00 00 04 00 00 00 01 00 00 00 1a 00 00 00 08 00 00 00 03 00 00 00 01 00 00 00 04 00 00 00 04 00 00 00 01 00 00 00 00 00 00 00 00 00 00 00 04 00 00 00 01 00 00 00 29 00 00 00 08 00 00 00 03 00 00 00 01 00 00 00 05 00 00 00 05 00 00 00 01 00 00 00 00 00 00 00 00 00 00 00 04 00 00 00 01 00 00 00 2a 00 00 00 08 00 00 00 03 00 00 00 01 00 00 00 06 00 00 00 06 00 00 00 01 00 00 00 00 00 00 00 00 00 00 00 04 00 00 00 01 00 00 00 0d 00 00 00 0b 00 00 00 03 00 00 00 08 00 00 00 07 00 00 00 07 00 00 00 01 00 00 00 00 00 00 00 00 00 00 00 04 00 00 00 01 00 00 00 0c 00 00 00 0b 00 00 00 03 00 00 00 08 00 00 00 08 00 00 00 08 00 00 00 01 00 00 00 00 00 00 00 00 00 00 00 04 00 00 00 01 00 00 00 2c 00 00 00 03 00 00 00 03 00 00 00 00 00 00 00 39 00 00 00 39 00 00 00 01 00 00 00 00 00 00 00 00 00 00 00 04 00 00 00 00 00 00 00 2d 00 00 00 0c 00 00 00 03 00 00 00 00 00 00 00 3a 00 00 00 3a 00 00 00 01 00 00 00 00 00 00 00 00 00 00 00 04 00 00 00 00 00 00 00 2f 00 00 00 02 00 00 00 03 00 00 00 00 00 00 00 3c 00 00 00 3c 00 00 00 01 00 00 00 00 00 00 00 00 00 00 00 04 00 00 00 00 00 00 00 26 00 00 00 05 00 00 00 03 00 00 00 0d 00 00 00 1b 00 00 00 1b 00 00 00 01 00 00 00 00 00 00 00 00 00 00 00 04 00 00 00 00 00 00 00 14 00 00 00 04 00 00 00 03 00 00 00 08 00 00 00 09 00 00 00 09 00 00 00 01 00 00 00 00 00 00 00 00 00 00 00 04 00 00 00 01 00 00 00 27 00 00 00 04 00 00 00 03 00 00 00 14 00 00 00 1c 00 00 00 1c 00 00 00 01 00 00 00 00 00 00 00 00 00 00 00 04 00 00 00 00 00 00 00 28 00 00 00 00 00 00 00 03 00 00 00 17 00 00 00 1d 00 00 00 1d 00 00 00 01 00 00 00 00 00 00 00 00 00 00 00 04 00 00 00 00 00 00 00 30 00 00 00 0e 00 00 00 03 00 00 00 00 00 00 00 3b 00 00 00 3b 00 00 00 01 00 00 00 00 00 00 00 00 00 00 00 04 00 00 00 00 00 00 00 31 00 00 00 0f 00 00 00 03 00 00 00 00 00 00 00 3e 00 00 00 3e 00 00 00 01 00 00 00 00 00 00 00 00 00 00 00 04 00 00 00 00 00 00 00 35 00 00 00 09 00 00 00 03 00 00 00 00 00 00 00 3f 00 00 00 3f 00 00 00 01 00 00 00 00 00 00 00 00 00 00 00 04 00 00 00 00 00 00 00 16 00 00 00 0b 00 00 00 03 00 00 00 ff ff 00 00 00 00 00 00 00 00 00 00 01 00 00 00 00 00 00 00 00 00 00 00 04 00 00 00 00 00 00 00];
		apple,tunable-dcs-wr-bwr-threshold = [00 00 07 00 33 b3 0e 00 66 66 14 00 33 33 1a 00 33 b3 1e 00];
		apple,tunable-agx-slow-af-wr-bw-dvfs-filter = [0e 00 00 00];
		apple,tunable-temp-sensor = [01 00 00 00 06 00 00 00 06 00 00 00 00 00 00 00 00 00 00 00 00 00 00 00 00 00 00 00 00 00 00 00 6e 00 00 00 7d 00 00 00 54 61 30 30 30 6d 00 00 00 00 00 00 00 00 00 00 02 00 00 00 06 00 00 00 03 00 00 00 00 00 00 00 00 00 00 00 00 00 00 00 00 00 00 00 00 00 00 00 6e 00 00 00 7d 00 00 00 54 65 30 30 30 6d 00 00 00 00 00 00 00 00 00 00 03 00 00 00 06 00 00 00 03 00 00 00 01 00 00 00 00 00 00 00 00 00 00 00 00 00 00 00 00 00 00 00 6e 00 00 00 7d 00 00 00 54 65 30 30 31 6d 00 00 00 00 00 00 00 00 00 00 04 00 00 00 06 00 00 00 04 00 00 00 00 00 00 00 00 00 00 00 00 00 00 00 00 00 00 00 00 00 00 00 6e 00 00 00 7d 00 00 00 54 70 30 30 30 6d 00 00 00 00 00 00 00 00 00 00 05 00 00 00 06 00 00 00 04 00 00 00 01 00 00 00 00 00 00 00 00 00 00 00 00 00 00 00 00 00 00 00 6e 00 00 00 7d 00 00 00 54 70 30 30 31 6d 00 00 00 00 00 00 00 00 00 00 06 00 00 00 06 00 00 00 04 00 00 00 02 00 00 00 00 00 00 00 00 00 00 00 00 00 00 00 00 00 00 00 6e 00 00 00 7d 00 00 00 54 70 30 30 32 6d 00 00 00 00 00 00 00 00 00 00 07 00 00 00 05 00 00 00 06 00 00 00 00 00 00 00 04 00 00 00 01 00 00 00 00 00 00 00 00 00 00 00 6e 00 00 00 7d 00 00 00 54 61 30 30 31 69 00 00 00 00 00 00 00 00 00 00 08 00 00 00 05 00 00 00 06 00 00 00 00 00 00 00 01 00 00 00 02 00 00 00 00 00 00 00 00 00 00 00 6e 00 00 00 7d 00 00 00 54 61 30 30 32 69 00 00 00 00 00 00 00 00 00 00 09 00 00 00 04 00 00 00 00 00 00 00 00 00 00 00 00 00 00 00 00 00 00 00 00 00 00 00 00 00 00 00 6e 00 00 00 7d 00 00 00 54 68 30 30 30 69 00 00 00 00 00 00 00 00 00 00 0a 00 00 00 04 00 00 00 00 00 00 00 00 00 00 00 01 00 00 00 00 00 00 00 00 00 00 00 00 00 00 00 6e 00 00 00 7d 00 00 00 54 68 30 30 31 69 00 00 00 00 00 00 00 00 00 00 0b 00 00 00 04 00 00 00 00 00 00 00 00 00 00 00 02 00 00 00 00 00 00 00 00 00 00 00 00 00 00 00 6e 00 00 00 7d 00 00 00 54 68 30 30 32 69 00 00 00 00 00 00 00 00 00 00 0c 00 00 00 01 00 00 00 05 00 00 00 00 00 00 00 00 00 00 00 00 00 00 00 00 00 00 00 00 00 00 00 6d 00 00 00 6d 00 00 00 4d 54 52 5f 54 4f 50 5f 41 47 58 00 00 00 00 00];
		apple,tunable-ptd-driver-version = [01 00 00 00];
		apple,tunable-agx-fast-af-rd-bw-threshold = [00 00 05 00 00 00 00 00 00 00 00 00 00 00 00 00 00 00 2c 00 00 00 00 00 00 00 04 00 06 00 00 00 00 00 00 00 00 00 00 00 00 00 2b 00 06 00 00 00];
		apple,tunable-agx-slow-af-rd-bw-threshold = [00 00 0e 00 00 00 00 00 00 00 00 00 00 00 00 00 00 00 4c 00 00 00 00 00 00 00 0d 00 06 00 00 00 00 00 00 00 00 00 00 00 00 00 4b 00 06 00 00 00];
		apple,tunable-ane-fast-dcs-bw-dvfs-filter = [c0 ff 1f 00];
		apple,tunable-ane-slow-af-bw-threshold = [47 a1 19 00 00 00 00 00 00 00 00 00 00 00 00 00 14 2e 22 00 00 00 00 00 47 a1 18 00 03 00 00 00 00 00 00 00 00 00 00 00 14 2e 21 00 03 00 00 00];
		apple,tunable-ane-slow-dcs-bw-dvfs-filter = [3f 00 00 00];
		apple,tunable-fast-die-ctrl-ts-avg-temp = [00 00 64 00];
		apple,tunable-lts-ctrl-loop = [01 00 00 00 00 00 00 00 00 00 00 00 00 00 00 00 00 00 00 00 01 00 00 00 01 00 00 00 00 00 00 00 02 00 00 00 03 00 00 00 00 00 00 00 00 00 00 00 00 00 00 00 00 00 00 00 00 00 00 00 00 00 00 00 00 00 00 00 00 00 00 00 00 00 00 00 00 00 00 00 00 00 00 00 00 00 00 00 00 00 00 00 00 00 00 00 45 41 43 43 00 00 00 00 00 00 00 00 00 00 00 00 02 00 00 00 00 00 00 00 01 00 00 00 01 00 00 00 01 00 00 00 02 00 00 00 02 00 00 00 01 00 00 00 04 00 00 00 05 00 00 00 06 00 00 00 00 00 00 00 00 00 00 00 00 00 00 00 00 00 00 00 00 00 00 00 00 00 00 00 00 00 00 00 00 00 00 00 00 00 00 00 00 00 00 00 00 00 00 00 00 00 00 00 00 00 00 00 50 41 43 43 00 00 00 00 00 00 00 00 00 00 00 00 03 00 00 00 00 00 00 00 02 00 00 00 02 00 00 00 00 00 00 00 00 00 00 00 04 00 00 00 00 00 00 00 0c 00 00 00 00 00 00 00 00 00 00 00 00 00 00 00 00 00 00 00 00 00 00 00 00 00 00 00 00 00 00 00 00 00 00 00 00 00 00 00 00 00 00 00 00 00 00 00 00 00 00 00 00 00 00 00 00 00 00 00 00 00 00 00 47 50 55 00 00 00 00 00 00 00 00 00 00 00 00 00];
		apple,tunable-pm-ptd-ranges = [01 00 00 00 02 00 00 00 03 00 00 00 04 00 00 00 05 00 00 00 06 00 00 00 07 00 00 00 00 00 00 00 00 00 00 00 09 00 00 00 0a 00 00 00 0b 00 00 00 0c 00 00 00 0d 00 00 00 00 00 00 00];
		apple,tunable-fast-die-ctrl-ts = [00 00 05 00];
		apple,tunable-agx-fast-af-rd-bw-dvfs-filter = [f0 03 00 00];
		apple,tunable-dcs-bwr-threshold = [33 b3 0b 00 00 80 18 00 99 19 22 00 33 b3 2b 00 33 33 33 00];
		apple,tunable-uuid = [45 46 44 36 30 32 38 34 2d 37 43 35 38 2d 33 33 41 39 2d 38 35 32 32 2d 43 42 33 33 36 36 41 46 36 30 34 30 00];
	};
};
